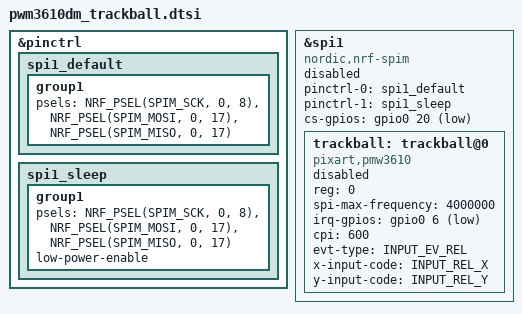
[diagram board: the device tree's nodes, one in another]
&pinctrl {
    spi1_default: spi1_default {
        group1 {
            psels = <NRF_PSEL(SPIM_SCK, 0, 8)>,
                <NRF_PSEL(SPIM_MOSI, 0, 17)>,
                <NRF_PSEL(SPIM_MISO, 0, 17)>;
        };
    };

    spi1_sleep: spi1_sleep {
        group1 {
            psels = <NRF_PSEL(SPIM_SCK, 0, 8)>,
                <NRF_PSEL(SPIM_MOSI, 0, 17)>,
                <NRF_PSEL(SPIM_MISO, 0, 17)>;
            low-power-enable;
        };
    };
};

&spi1 {
    status = "disabled";
    compatible = "nordic,nrf-spim";
    pinctrl-0 = <&spi1_default>;
    pinctrl-1 = <&spi1_sleep>;
    pinctrl-names = "default", "sleep";
    cs-gpios = <&gpio0 20 GPIO_ACTIVE_LOW>;

    trackball: trackball@0 {
        status = "disabled";
        compatible = "pixart,pmw3610";
        reg = <0>;
        spi-max-frequency = <4000000>;
        irq-gpios = <&gpio0 6 (GPIO_ACTIVE_LOW | GPIO_PULL_UP)>;
        cpi = <600>;
        evt-type = <INPUT_EV_REL>;
        x-input-code = <INPUT_REL_X>;
        y-input-code = <INPUT_REL_Y>;
    };
};

